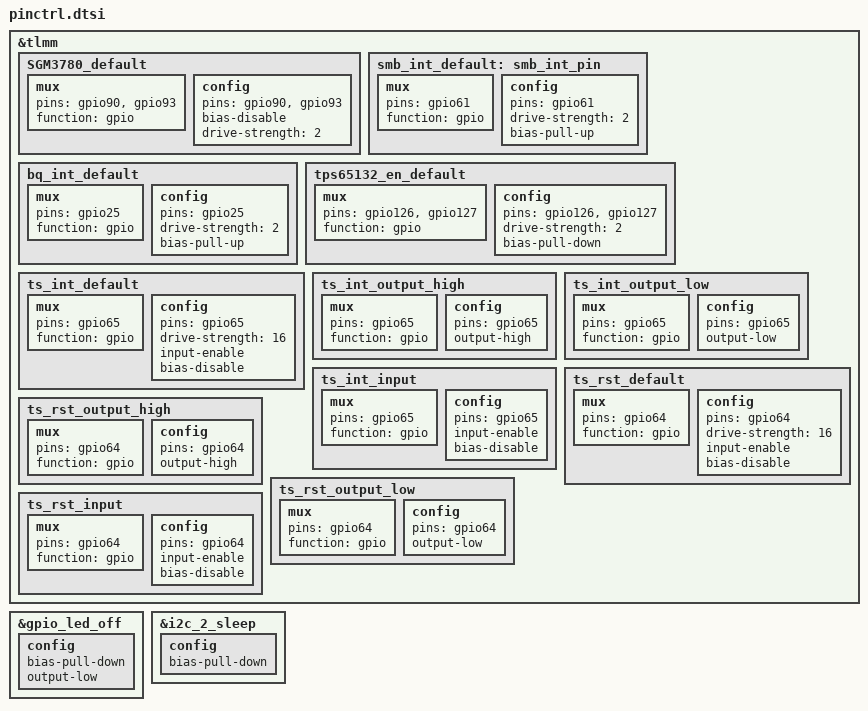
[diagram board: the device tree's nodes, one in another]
/* From stock msm8917-camera-pinctrl.dtsi */
&tlmm {
	SGM3780_default: SGM3780_default {
		mux {
			pins = "gpio90", "gpio93";
			function = "gpio";
		};

		config {
			pins = "gpio90", "gpio93";
			bias-disable; /* No PULL */
			drive-strength = <2>; /* 2 MA */
		};
	};
};

/* From stock msm8917-pinctrl.dtsi */
&tlmm {
	smb_int_default: smb_int_pin {
		mux {
			pins = "gpio61";
			function = "gpio";
		};
		config {
			pins = "gpio61";
			drive-strength = <2>;	/*8 MA */
			bias-pull-up;		/* PULL UP*/
		};
	};
	bq_int_default: bq_int_default {
		mux {
			pins = "gpio25";
			function ="gpio";
		};
		config {
			pins = "gpio25";
			drive-strength = <2>; /* 2 MA */
			bias-pull-up;
			/* PULL UP*/
			};
	};
	tps65132_en_default: tps65132_en_default {
		mux {
			pins = "gpio126", "gpio127";
			function = "gpio";
		};
		config {
			pins = "gpio126", "gpio127";
			drive-strength = <2>;
			bias-pull-down;
		};
	};
};
&gpio_led_off {
	config {
		bias-pull-down;
		output-low;
	};
};
&i2c_2_sleep {
	config {
		/delete-property/ bias-disable;
		bias-pull-down;
	};
};

/* Custom */
&tlmm {
	/* add pingrp for goodix touch */
	ts_int_default: ts_int_default {
		mux {
			pins = "gpio65";
			function = "gpio";
		};
		config {
			pins = "gpio65";
			drive-strength = <16>;
			/*bias-pull-up;*/
			input-enable;
			bias-disable;
		};
	};

	ts_int_output_high: ts_int_output_high {
		mux {
			pins = "gpio65";
			function = "gpio";
		};
		config {
			pins = "gpio65";
			output-high;
		};
	};

	ts_int_output_low: ts_int_output_low {
		mux {
			pins = "gpio65";
			function = "gpio";
		};
		config {
			pins = "gpio65";
			output-low;
		};
	};

	ts_int_input: ts_int_input {
		mux {
			pins = "gpio65";
			function = "gpio";
		};
		config {
			pins = "gpio65";
			input-enable;
			bias-disable;
		};
	};

	ts_rst_default: ts_rst_default {
		mux {
			pins = "gpio64";
			function = "gpio";
		};
		config {
			pins = "gpio64";
			drive-strength = <16>;
			/*bias-pull-up;*/
			input-enable;
			bias-disable;
		};
	};

	ts_rst_output_high: ts_rst_output_high {
		mux {
			pins = "gpio64";
			function = "gpio";
		};
		config {
			pins = "gpio64";
			output-high;
		};
	};

	ts_rst_output_low: ts_rst_output_low {
		mux {
			pins = "gpio64";
			function = "gpio";
		};
		config {
			pins = "gpio64";
			output-low;
		};
	};

	ts_rst_input: ts_rst_input {
		mux {
			pins = "gpio64";
			function = "gpio";
		};
		config {
			pins = "gpio64";
			input-enable;
			bias-disable;
		};
	};
};
